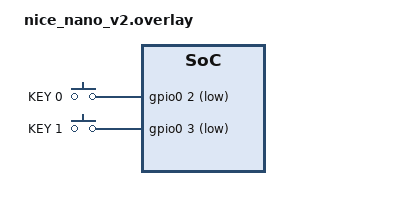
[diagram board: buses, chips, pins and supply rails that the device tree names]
/ {
    buttons {
        compatible = "gpio-keys";

        key0: key_0 {
            gpios = <&gpio0 2 (GPIO_ACTIVE_LOW | GPIO_PULL_UP)>;
            label = "KEY 0";
        };

        key1: key_1 {
            gpios = <&gpio0 3 (GPIO_ACTIVE_LOW | GPIO_PULL_UP)>;
            label = "KEY 1";
        };
    };
};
